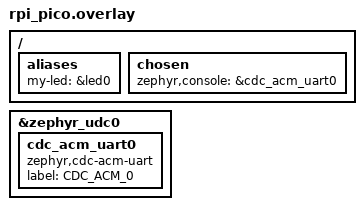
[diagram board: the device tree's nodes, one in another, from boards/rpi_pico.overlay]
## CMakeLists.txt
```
# Minimum CMake version
cmake_minimum_required(VERSION 3.22.0)

# Add extra application modules
#set(EXTRA_ZEPHYR_MODULES "${CMAKE_SOURCE_DIR}/modules/say_hello")
set(EXTRA_ZEPHYR_MODULES "${CMAKE_SOURCE_DIR}/modules/say_hello;/workspace/modules/si5351")
set(EXTRA_DTC_OVERLAY_FILE "app.overlay")

# Locate the Zephyr RTOS source
find_package(Zephyr REQUIRED HINTS $ENV{ZEPHYR_BASE})

# Name the project
project(blink)

# Locate the source code for the application
target_sources(app PRIVATE src/main.c)
target_sources(app PRIVATE src/commands/si5351_shell.c)
```

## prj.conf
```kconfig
CONFIG_STACK_POINTER_RANDOM=0
CONFIG_TEST_RANDOM_GENERATOR=y
CONFIG_TIMER_RANDOM_GENERATOR=y
CONFIG_TEST_CSPRNG_GENERATOR=y
CONFIG_SAY_HELLO=y

CONFIG_ADC_INIT_PRIORITY=50
CONFIG_ADC=y

# Activate I2C, Shell and I2C shell
CONFIG_I2C=y
CONFIG_I2C_SHELL=y
CONFIG_SHELL=y

CONFIG_SENSOR=y
CONFIG_SENSOR_SHELL=y

# This is uneccessary since the driver is device-tree aware and will enable by default
#CONFIG_CLOCK_CONTROL_SI5351=n
CONFIG_CLOCK_CONTROL_LOG_LEVEL_DBG=y

# Using Picolibc
#Memory region         Used Size  Region Size  %age Used
#           FLASH:       23112 B       256 KB      8.82%
#             RAM:        4992 B        40 KB     12.19%
#             CCM:          0 GB         8 KB      0.00%
#        IDT_LIST:          0 GB        32 KB      0.00%
##CONFIG_CURRENT_THREAD_USE_TLS=y
##CONFIG_THREAD_LOCAL_STORAGE=y
##CONFIG_PICOLIBC=y
### CONFIG_NEWLIB_LIBC is not set
##CONFIG_PICOLIBC_USE_TOOLCHAIN=y
##CONFIG_PICOLIBC_IO_FLOAT=y

# Using Newlibc
#Memory region         Used Size  Region Size  %age Used
#           FLASH:       20996 B       256 KB      8.01%
#             RAM:        4992 B        40 KB     12.19%
#             CCM:          0 GB         8 KB      0.00%
#        IDT_LIST:          0 GB        32 KB      0.00%
CONFIG_ERRNO_IN_TLS=y
# CONFIG_PICOLIBC is not set
CONFIG_NEWLIB_LIBC=y
# CONFIG_NEWLIB_LIBC_NANO is not set
CONFIG_NEWLIB_LIBC_MIN_REQUIRED_HEAP_SIZE=8192
CONFIG_NEWLIB_LIBC_FLOAT_PRINTF=y
# CONFIG_NEWLIB_LIBC_FLOAT_SCANF is not set
# CONFIG_NEWLIB_LIBC_HEAP_LISTENER is not set
# CONFIG_NEWLIB_LIBC_CUSTOM_SBRK is not set
# CONFIG_CBPRINTF_FP_ALWAYS_A is not set
CONFIG_CBPRINTF_N_SPECIFIER=y
```

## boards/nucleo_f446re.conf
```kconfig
CONFIG_FPU=y
CONFIG_FP_HARDABI=y
# CONFIG_FP_SOFTABI is not set
CONFIG_FPU_SHARING=y
## CONFIG_LEGACY_GENERATED_INCLUDE_PATH is not set    
CONFIG_LEGACY_GENERATED_INCLUDE_PATH=n
```

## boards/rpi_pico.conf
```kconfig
CONFIG_USB_DEVICE_STACK=y
CONFIG_USB_DEVICE_VID=0x2FE3
CONFIG_USB_DEVICE_PID=0x0004
CONFIG_USB_DEVICE_PRODUCT="USB CDC-ACM serial console"
CONFIG_USB_DEVICE_INITIALIZE_AT_BOOT=y
```

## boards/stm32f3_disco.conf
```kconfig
CONFIG_FPU=y
CONFIG_FP_HARDABI=y
# CONFIG_FP_SOFTABI is not set
CONFIG_FPU_SHARING=y

# CONFIG_ADC_ASYNC is not set
CONFIG_ADC_STM32=y
# CONFIG_ADC_STM32_DMA is not set


CONFIG_LOG=y
CONFIG_LOG_THREAD_ID_PREFIX=y
CONFIG_LOG_CMDS=y
```

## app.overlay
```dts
/ {
    dude {
        compatible = "my,useless-binding";
        status = "okay";
        num-dudes = <1>;
        //not-allowed = <3>;
    };
};
```

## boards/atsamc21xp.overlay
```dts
/ {
    aliases {
        my-led = &led0;
    };
};
```

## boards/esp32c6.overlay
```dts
/ {
    aliases {
        my-led = &led0;
    };

    leds {
        compatible = "gpio-leds";
        led0: d13 {
            gpios = <&gpio0 5 GPIO_ACTIVE_HIGH>;
        };
    };
};
```

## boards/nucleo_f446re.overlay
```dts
/ {
    aliases {
        my-led = &green_led_2;
    };
};
```

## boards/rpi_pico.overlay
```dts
/ {
    aliases {
        my-led = &led0;
    };

    chosen {
        zephyr,console = &cdc_acm_uart0;
    };
};

&zephyr_udc0 {
    cdc_acm_uart0: cdc_acm_uart0 {
        compatible = "zephyr,cdc-acm-uart";
        label = "CDC_ACM_0";
    };
};
```

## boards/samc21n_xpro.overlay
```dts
/ {
    aliases {
        my-led = &led0;
    };
};

&led0 {
    gpios = <&porta 15 GPIO_ACTIVE_LOW>;
    label = "Yellow LED";
};
```

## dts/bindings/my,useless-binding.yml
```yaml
# It is possible to have comments here
description: Description is apparently mandatory

compatible: "my,useless-binding"

properties:
  num-dudes:
    type: int
    required: true
```

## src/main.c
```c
#include <stdio.h>
#include <stdint.h>
#include <zephyr/drivers/gpio.h>
#include <zephyr/drivers/clock_control.h>
#include <zephyr/kernel.h>
#include <zephyr/random/random.h>
#include <zephyr/device.h>
#include <zephyr/devicetree.h>
#include <zephyr/drivers/i2c.h>
#include <zephyr/logging/log.h>
#include "say_hello.h"

#include <zephyr/drivers/clock_control/si5351.h>

// Settings
static const int32_t sleep_time_ms = 100;
static const struct gpio_dt_spec led = GPIO_DT_SPEC_GET(DT_ALIAS(my_led), gpios);
static const struct gpio_dt_spec btn = GPIO_DT_SPEC_GET(DT_ALIAS(sw0), gpios);

__attribute__((unused)) static int read(uint8_t devaddr, uint8_t regaddr, uint8_t *regval)
{
	int ret;

	const struct device *dev = DEVICE_DT_GET(DT_NODELABEL(i2c1));

	if (!device_is_ready(dev))
	{
		// LOG_ERR("Device not ready");
		return -ENODEV;
	}

	ret = i2c_write_read(dev, devaddr, &regaddr, 1, regval, 1);
	if (ret)
	{
		// LOG_ERR("Call `i2c_write_read` failed: %d", ret);
		return ret;
	}

	return 0;
}

__attribute__((unused)) static int write(uint8_t devaddr, uint8_t regaddr, uint8_t regval)
{
	int ret;

	const struct device *dev = DEVICE_DT_GET(DT_NODELABEL(i2c1));

	if (!device_is_ready(dev))
	{
		// LOG_ERR("Device not ready");
		return -ENODEV;
	}

	uint8_t buf[2] = {regaddr, regval};

	ret = i2c_write(dev, buf, 2, devaddr);
	if (ret)
	{
		// LOG_ERR("Call `i2c_write` failed: %d", ret);
		return ret;
	}

	return 0;
}

int main(void)
{
	int ret;
	int state = 0;
	int button_state = 0, last_button_state = 0;
	uint32_t rnd;
	double dbl;

	const struct device *clock_generator_1 = DEVICE_DT_GET(DT_NODELABEL(cg1));
	const struct device *clock_output_1 = DEVICE_DT_GET(DT_NODELABEL(clkout0));
	const struct device *clock_output_2 = DEVICE_DT_GET(DT_NODELABEL(clkout1));

	// Make sure that the GPIO was initialized
	if (!gpio_is_ready_dt(&led))
	{
		return 0;
	}

	// Make sure that the button was initialized
	if (!gpio_is_ready_dt(&btn))
	{
		printk("ERROR: button not ready\r\n");
		return 0;
	}

	if (!device_is_ready(clock_generator_1))
	{
		printk("ERROR: Clock generator is not ready\r\n");
		return 0;
	}

	if (!device_is_ready(clock_output_1))
	{
		printk("ERROR: Clock output 1 is not ready\r\n");
		return 0;
	}

	if (!device_is_ready(clock_output_2))
	{
		printk("ERROR: Clock output 2 is not ready\r\n");
		return 0;
	}

	// Set the button as input (apply extra flags if needed)
	ret = gpio_pin_configure_dt(&btn, GPIO_INPUT);
	if (ret < 0)
	{
		return 0;
	}

	// Set the GPIO as output
	ret = gpio_pin_configure_dt(&led, GPIO_OUTPUT);
	if (ret < 0)
	{
		return 0;
	}

	printk("Up and running I think!\n");

	// Do forever
	while (1)
	{

		// Change the state of the pin and print
		state = !state;
		rnd = sys_rand32_get();
		dbl = (double)rnd / UINT32_MAX;

		// printk("LED state: %d\r\n", state);
		// printk("Random value: %u\r\n", rnd);
		// printk("Random double value: %f\r\n", dbl);

		// say_hello();

		// Set pin state
		ret = gpio_pin_set_dt(&led, state);
		if (ret < 0)
		{
			return 0;
		}

		// Poll button state
		button_state = gpio_pin_get_dt(&btn);
		if (button_state < 0)
		{
			printk("Error %d: failed to read button pin\r\n", button_state);
		}
		else if (button_state != last_button_state)
		{
			// printk("Button state: %d\r\n", button_state);

			if (button_state == 0)
			{
				// Button pressed
				// write(0x60, 0x10, 0x0c); // Turn on clock1
				// write(0x60, 0x11, 0x0c); // Turn on clock1

				clock_control_on(clock_output_1, NULL);
				clock_control_on(clock_output_2, NULL);
			}
			else
			{
				// Button released
				// write(0x60, 0x10, 0x8c); // Turn off clock1
				// write(0x60, 0x11, 0x8c); // Turn off clock1

				clock_control_off(clock_output_1, NULL);
				clock_control_off(clock_output_2, NULL);
			}

			last_button_state = button_state;
		}

		// Sleep
		k_msleep(sleep_time_ms);
	}

	return 0;
}
```
